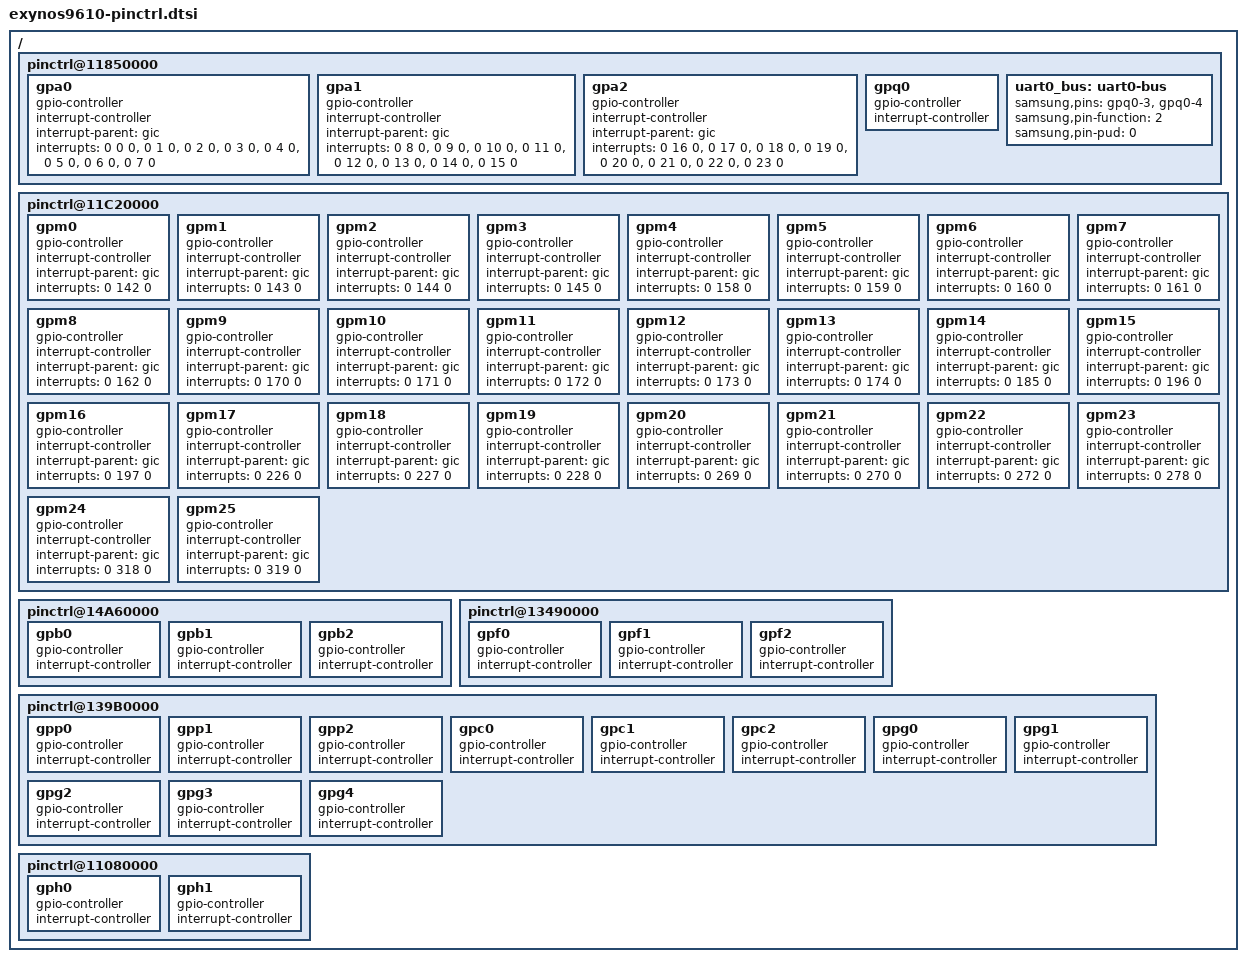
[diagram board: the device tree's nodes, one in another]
/*
 * Samsung's Exynos9610 SoC pin-mux and pin-config device tree source
 *
 * Copyright (c) 2017 Samsung Electronics Co., Ltd.
 *		http://www.samsung.com
 *
 * Samsung's Exynos9610 SoC pin-mux and pin-config options are listed as device
 * tree nodes are listed in this file.
 *
 * This program is free software; you can redistribute it and/or modify
 * it under the terms of the GNU General Public License version 2 as
 * published by the Free Software Foundation.
 */

/ {
	/* ALIVE */
	pinctrl@11850000 {
		gpa0: gpa0 {
			gpio-controller;
			#gpio-cells = <2>;

			interrupt-controller;
			#interrupt-cells = <3>;
			interrupt-parent = <&gic>;
			interrupts = <0 0 0>, <0 1 0>, <0 2 0>, <0 3 0>,
				     <0 4 0>, <0 5 0>, <0 6 0>, <0 7 0>;
		};

		gpa1: gpa1 {
			gpio-controller;
			#gpio-cells = <2>;

			interrupt-controller;
			#interrupt-cells = <3>;
			interrupt-parent = <&gic>;
			interrupts = <0 8 0>, <0 9 0>, <0 10 0>, <0 11 0>,
				     <0 12 0>, <0 13 0>, <0 14 0>, <0 15 0>;
		};

		gpa2: gpa2 {
			gpio-controller;
			#gpio-cells = <2>;

			interrupt-controller;
			#interrupt-cells = <3>;
			interrupt-parent = <&gic>;
			interrupts = <0 16 0>, <0 17 0>, <0 18 0>, <0 19 0>,
				     <0 20 0>, <0 21 0>, <0 22 0>, <0 23 0>;
		};

		gpq0: gpq0 {
			gpio-controller;
			#gpio-cells = <2>;

			interrupt-controller;
			#interrupt-cells = <2>;
		};

		/* USI_PERIC0_UART_DBG */
		uart0_bus: uart0-bus {
			samsung,pins = "gpq0-3", "gpq0-4";
			samsung,pin-function = <2>;
			samsung,pin-pud = <0>;
		};
	};

	/* CMGP */
	pinctrl@11C20000{
		gpm0: gpm0 {
			gpio-controller;
			#gpio-cells = <2>;

			interrupt-controller;
			#interrupt-cells = <3>;
			interrupt-parent = <&gic>;
			interrupts = <0 142 0>;
		};

		gpm1: gpm1 {
			gpio-controller;
			#gpio-cells = <2>;

			interrupt-controller;
			#interrupt-cells = <3>;
			interrupt-parent = <&gic>;
			interrupts = <0 143 0>;
		};

		gpm2: gpm2 {
			gpio-controller;
			#gpio-cells = <2>;

			interrupt-controller;
			#interrupt-cells = <3>;
			interrupt-parent = <&gic>;
			interrupts = <0 144 0>;
		};

		gpm3: gpm3 {
			gpio-controller;
			#gpio-cells = <2>;

			interrupt-controller;
			#interrupt-cells = <3>;
			interrupt-parent = <&gic>;
			interrupts = <0 145 0>;
		};

		gpm4: gpm4 {
			gpio-controller;
			#gpio-cells = <2>;

			interrupt-controller;
			#interrupt-cells = <3>;
			interrupt-parent = <&gic>;
			interrupts = <0 158 0>;
		};

		gpm5: gpm5 {
			gpio-controller;
			#gpio-cells = <2>;

			interrupt-controller;
			#interrupt-cells = <3>;
			interrupt-parent = <&gic>;
			interrupts = <0 159 0>;
		};

		gpm6: gpm6 {
			gpio-controller;
			#gpio-cells = <2>;

			interrupt-controller;
			#interrupt-cells = <3>;
			interrupt-parent = <&gic>;
			interrupts = <0 160 0>;
		};

		gpm7: gpm7 {
			gpio-controller;
			#gpio-cells = <2>;

			interrupt-controller;
			#interrupt-cells = <3>;
			interrupt-parent = <&gic>;
			interrupts = <0 161 0>;
		};

		gpm8: gpm8 {
			gpio-controller;
			#gpio-cells = <2>;

			interrupt-controller;
			#interrupt-cells = <3>;
			interrupt-parent = <&gic>;
			interrupts = <0 162 0>;
		};

		gpm9: gpm9 {
			gpio-controller;
			#gpio-cells = <2>;

			interrupt-controller;
			#interrupt-cells = <3>;
			interrupt-parent = <&gic>;
			interrupts = <0 170 0>;
		};

		gpm10: gpm10 {
			gpio-controller;
			#gpio-cells = <2>;

			interrupt-controller;
			#interrupt-cells = <3>;
			interrupt-parent = <&gic>;
			interrupts = <0 171 0>;
		};

		gpm11: gpm11 {
			gpio-controller;
			#gpio-cells = <2>;

			interrupt-controller;
			#interrupt-cells = <3>;
			interrupt-parent = <&gic>;
			interrupts = <0 172 0>;
		};

		gpm12: gpm12 {
			gpio-controller;
			#gpio-cells = <2>;

			interrupt-controller;
			#interrupt-cells = <3>;
			interrupt-parent = <&gic>;
			interrupts = <0 173 0>;
		};

		gpm13: gpm13 {
			gpio-controller;
			#gpio-cells = <2>;

			interrupt-controller;
			#interrupt-cells = <3>;
			interrupt-parent = <&gic>;
			interrupts = <0 174 0>;
		};

		gpm14: gpm14 {
			gpio-controller;
			#gpio-cells = <2>;

			interrupt-controller;
			#interrupt-cells = <3>;
			interrupt-parent = <&gic>;
			interrupts = <0 185 0>;
		};

		gpm15: gpm15 {
			gpio-controller;
			#gpio-cells = <2>;

			interrupt-controller;
			#interrupt-cells = <3>;
			interrupt-parent = <&gic>;
			interrupts = <0 196 0>;
		};

		gpm16: gpm16 {
			gpio-controller;
			#gpio-cells = <2>;

			interrupt-controller;
			#interrupt-cells = <3>;
			interrupt-parent = <&gic>;
			interrupts = <0 197 0>;
		};

		gpm17: gpm17 {
			gpio-controller;
			#gpio-cells = <2>;

			interrupt-controller;
			#interrupt-cells = <3>;
			interrupt-parent = <&gic>;
			interrupts = <0 226 0>;
		};
		gpm18: gpm18 {
			gpio-controller;
			#gpio-cells = <2>;

			interrupt-controller;
			#interrupt-cells = <3>;
			interrupt-parent = <&gic>;
			interrupts = <0 227 0>;
		};

		gpm19: gpm19 {
			gpio-controller;
			#gpio-cells = <2>;

			interrupt-controller;
			#interrupt-cells = <3>;
			interrupt-parent = <&gic>;
			interrupts = <0 228 0>;
		};

		gpm20: gpm20 {
			gpio-controller;
			#gpio-cells = <2>;

			interrupt-controller;
			#interrupt-cells = <3>;
			interrupt-parent = <&gic>;
			interrupts = <0 269 0>;
		};

		gpm21: gpm21 {
			gpio-controller;
			#gpio-cells = <2>;

			interrupt-controller;
			#interrupt-cells = <3>;
			interrupt-parent = <&gic>;
			interrupts = <0 270 0>;
		};

		gpm22: gpm22 {
			gpio-controller;
			#gpio-cells = <2>;

			interrupt-controller;
			#interrupt-cells = <3>;
			interrupt-parent = <&gic>;
			interrupts = <0 272 0>;
		};

		gpm23: gpm23 {
			gpio-controller;
			#gpio-cells = <2>;

			interrupt-controller;
			#interrupt-cells = <3>;
			interrupt-parent = <&gic>;
			interrupts = <0 278 0>;
		};

		gpm24: gpm24 {
			gpio-controller;
			#gpio-cells = <2>;

			interrupt-controller;
			#interrupt-cells = <3>;
			interrupt-parent = <&gic>;
			interrupts = <0 318 0>;
		};

		gpm25: gpm25 {
			gpio-controller;
			#gpio-cells = <2>;

			interrupt-controller;
			#interrupt-cells = <3>;
			interrupt-parent = <&gic>;
			interrupts = <0 319 0>;
		};

	};

	/* DISPAUD */
	pinctrl@14A60000{
		gpb0: gpb0 {
			gpio-controller;
			#gpio-cells = <2>;

			interrupt-controller;
			#interrupt-cells = <2>;
		};

		gpb1: gpb1 {
			gpio-controller;
			#gpio-cells = <2>;

			interrupt-controller;
			#interrupt-cells = <2>;
		};

		gpb2: gpb2 {
			gpio-controller;
			#gpio-cells = <2>;

			interrupt-controller;
			#interrupt-cells = <2>;
		};
	};

	/* FSYS */
	pinctrl@13490000 {
		gpf0: gpf0 {
			gpio-controller;
			#gpio-cells = <2>;

			interrupt-controller;
			#interrupt-cells = <2>;
		};
		gpf1: gpf1 {
			gpio-controller;
			#gpio-cells = <2>;

			interrupt-controller;
			#interrupt-cells = <2>;
		};
		gpf2: gpf2 {
			gpio-controller;
			#gpio-cells = <2>;

			interrupt-controller;
			#interrupt-cells = <2>;
		};

	};

	/* TOP */
	pinctrl@139B0000 {
		gpp0: gpp0 {
			gpio-controller;
			#gpio-cells = <2>;

			interrupt-controller;
			#interrupt-cells = <2>;
		};

		gpp1: gpp1 {
			gpio-controller;
			#gpio-cells = <2>;

			interrupt-controller;
			#interrupt-cells = <2>;
		};

		gpp2: gpp2 {
			gpio-controller;
			#gpio-cells = <2>;

			interrupt-controller;
			#interrupt-cells = <2>;
		};

		gpc0: gpc0 {
			gpio-controller;
			#gpio-cells = <2>;

			interrupt-controller;
			#interrupt-cells = <2>;
		};

		gpc1: gpc1 {
			gpio-controller;
			#gpio-cells = <2>;

			interrupt-controller;
			#interrupt-cells = <2>;
		};

		gpc2: gpc2 {
			gpio-controller;
			#gpio-cells = <2>;

			interrupt-controller;
			#interrupt-cells = <2>;
		};

		gpg0: gpg0 {
			gpio-controller;
			#gpio-cells = <2>;

			interrupt-controller;
			#interrupt-cells = <2>;
		};

		gpg1: gpg1 {
			gpio-controller;
			#gpio-cells = <2>;

			interrupt-controller;
			#interrupt-cells = <2>;
		};

		gpg2: gpg2 {
			gpio-controller;
			#gpio-cells = <2>;

			interrupt-controller;
			#interrupt-cells = <2>;
		};

		gpg3: gpg3 {
			gpio-controller;
			#gpio-cells = <2>;

			interrupt-controller;
			#interrupt-cells = <2>;
		};

		gpg4: gpg4 {
			gpio-controller;
			#gpio-cells = <2>;

			interrupt-controller;
			#interrupt-cells = <2>;
		};

	};

	/* SHUB */
	pinctrl@11080000{
		gph0: gph0 {
			gpio-controller;
			#gpio-cells = <2>;

			interrupt-controller;
			#interrupt-cells = <2>;
		};

		gph1: gph1 {
			gpio-controller;
			#gpio-cells = <2>;

			interrupt-controller;
			#interrupt-cells = <2>;
		};
	};
};
